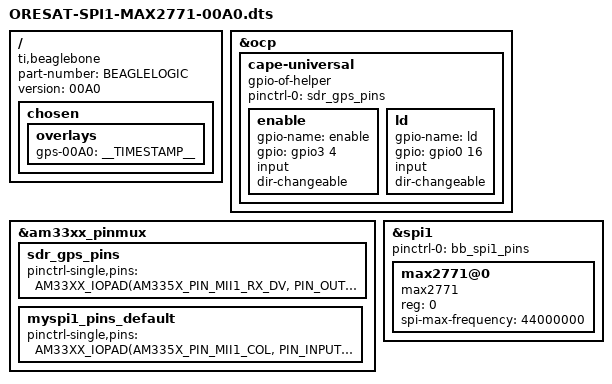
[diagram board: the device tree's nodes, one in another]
/* OreSat MAX2771 SPI1 DT Overlay */

#include <dt-bindings/pinctrl/am33xx.h>

/dts-v1/;
/plugin/;

/ {
    compatible = "ti,beaglebone", "ti,beaglebone-black", "ti,beaglebone-green";

    /* Identification */
    part-number = "BEAGLELOGIC";
    version = "00A0";

    fragment@0 {
        target-path="/";
        __overlay__ {
            chosen {
                overlays {
                    gps-00A0 = __TIMESTAMP__;
	        };
            };
        };
    };

    /* Enable MAX2271 GPIO */
    fragment@1 {
        target = <&ocp>;
        __overlay__ {
            cape-universal {
                compatible = "gpio-of-helper";
                status = "okay";
                pinctrl-names = "default";
                pinctrl-0 = <&sdr_gps_pins>; /* this must point to pinmux name below */

                enable {
                    gpio-name = "enable";
                    gpio = <&gpio3 4 0>; /* mii1_rx_dv */
                    input;
                    dir-changeable;
                };

                ld {
                    gpio-name = "ld";
                    gpio = <&gpio0 16 0>; /* mii1_txd3 */
                    input;
                    dir-changeable;
                };
            };
        };
    };

    /* MAX2271 GPIO pinmux */
    fragment@2 {
        target = <&am33xx_pinmux>;
        __overlay__ {
            sdr_gps_pins: sdr_gps_pins {
                pinctrl-single,pins = <
	            AM33XX_IOPAD(AM335X_PIN_MII1_RX_DV, PIN_OUT | INPUT_EN | MUX_MODE7) /* (L19) gmii1_rxdv.gpio3[4] */
                    AM33XX_IOPAD(AM335X_PIN_MII1_TXD3, PIN_INPUT | MUX_MODE7) /* (M17) gmii1_txd3.gpio0[16] */
                >;
            };
        };
    };

    /* MAX2271 SPI1 pinmux */
    fragment@3 {
        target = <&am33xx_pinmux>;
        __overlay__ {
            myspi1_pins_default: myspi1_pins_default {
                pinctrl-single,pins = <
                    AM33XX_IOPAD(AM335X_PIN_MII1_COL, PIN_INPUT | MUX_MODE2) /* (J19) gmii1_col.spi1_sclk */
                    AM33XX_IOPAD(AM335X_PIN_MII1_CRS, PIN_INPUT | MUX_MODE2) /* (J18) gmii1_crs.spi1_d0 */
                    AM33XX_IOPAD(AM335X_PIN_MII1_REF_CLK, PIN_INPUT | MUX_MODE2) /* (K18) rmii1_refclk.spi1_cs0 */
                >;
            };
        };
    };

    /* MAX2271 SPI1 settings */
    fragment@4 {
        target = <&spi1>;
        __overlay__ {
            #address-cells = <1>;
            #size-cells = <0>;

            status = "okay";
            pinctrl-names = "default";
            pinctrl-0 = <&bb_spi1_pins>;

            max2771@0{
                status = "okay";
                compatible = "max2771";
                reg = <0>;
                spi-max-frequency = <44000000>;
            };
        };
    };
};
